# AVR16EB20 device description
Architecture: AVR8X; Family: AVREB
Registers are 8-bit, read-write, reset 0x0 unless marked. A register's access mark holds for its fields unless they carry their own. Offsets are from the block's base; [hi:lo] are bit positions.

## CLKCTRL — Clock controller
Instances: CLKCTRL 0x0060
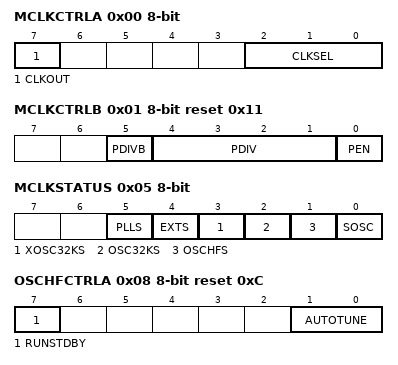
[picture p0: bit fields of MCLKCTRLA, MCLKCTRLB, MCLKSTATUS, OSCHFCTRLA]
0x00 MCLKCTRLA — MCLK Control A
  [7] CLKOUT — System clock out
  [2:0] CLKSEL — Clock select
    0=OSCHF (Internal high-frequency oscillator); 1=OSC32K (Internal 32.768 kHz oscillator); 2=XOSC32K (32.768 kHz crystal oscillator); 3=EXTCLK (External clock); 4=PLL (PLL Oscillator)
0x01 MCLKCTRLB reset 0x11 — MCLK Control B
  [5] PDIVB — Prescaler B division
    0=NONE (No division); 1=DIV4 (Divide by 4)
  [4:1] PDIV — Prescaler division
    0=DIV2 (Divide by 2); 1=DIV4 (Divide by 4); 2=DIV8 (Divide by 8); 3=DIV16 (Divide by 16); 4=DIV32 (Divide by 32); 5=DIV64 (Divide by 64); 8=DIV6 (Divide by 6); 9=DIV10 (Divide by 10); 10=DIV12 (Divide by 12); 11=DIV24 (Divide by 24); 12=DIV48 (Divide by 48)
  [0] PEN — Prescaler enable
0x05 MCLKSTATUS
  [5] PLLS ro — PLL status
  [4] EXTS ro — External Clock status
  [3] XOSC32KS ro — 32.768 kHz Crystal Oscillator status
  [2] OSC32KS ro — 32KHz oscillator status
  [1] OSCHFS ro — High frequency oscillator status
  [0] SOSC ro — System Oscillator changing
0x06 MCLKTIMEBASE
  [4:0] TIMEBASE
0x08 OSCHFCTRLA reset 0xC — OSCHF Control A
  [7] RUNSTDBY — Run in standby
  [1:0] AUTOTUNE — Automatic Oscillator Tune
    0=OFF (Disabled); 1=XOSC32K (Tune against 32.768 kHz Crystal Oscillator)
0x09 OSCHFTUNE
  [7:0] TUNE — Oscillator Tune
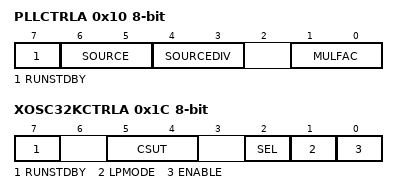
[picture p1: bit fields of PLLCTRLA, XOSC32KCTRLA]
0x10 PLLCTRLA — PLL Control A
  [7] RUNSTDBY — Run in Standby
  [6:5] SOURCE — PLL Source
    0=OSCHF (Internal High Frequency Oscillator); 1=EXTCLK (External Clock)
  [4:3] SOURCEDIV — PLL Source Division
    0=DIV1 (Source undivided); 1=DIV2 (Divide source by 2); 2=DIV4 (Divide source by 4); 3=DIV6 (Divide source by 6)
  [1:0] MULFAC — PLL Multiplication Factor
    0=OFF (PLL Disabled); 2=8X (Multiply by 8); 3=16X (Multiply by 16)
0x11 PLLCTRLB — PLL Control B
  [0] CLKDIV — PLL Output Clock Division
    0=NONE (PLL output clock undivided); 1=DIV2 (PLL output clock divided by 2)
0x18 OSC32KCTRLA — OSC32K Control A
  [7] RUNSTDBY — Run standby
0x1C XOSC32KCTRLA — XOSC32K Control A
  [7] RUNSTDBY — Run standby
  [5:4] CSUT — Crystal startup time
    0=1K (1k cycles); 1=16K (16k cycles); 2=32K (32k cycles); 3=64K (64k cycles)
  [2] SEL — Select
  [1] LPMODE — Low power mode
  [0] ENABLE

## CPU
Instances: CPU 0x0030
0x04 CCP — Configuration Change Protection
  [7:0] CCP — CCP signature
    157=SPM (SPM Instruction Protection); 216=IOREG (IO Register Protection)
0x0D SP 16-bit reset 0x7FFF — Stack Pointer
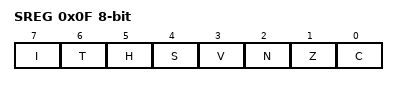
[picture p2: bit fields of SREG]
0x0F SREG — Status Register
  [7] I — Global Interrupt Enable Flag
  [6] T — Transfer Bit
  [5] H — Half Carry Flag
  [4] S — N Exclusive Or V Flag
  [3] V — Two's Complement Overflow Flag
  [2] N — Negative Flag
  [1] Z — Zero Flag
  [0] C — Carry Flag

## CPUINT — Interrupt Controller
Instances: CPUINT 0x0110
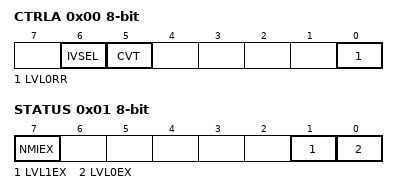
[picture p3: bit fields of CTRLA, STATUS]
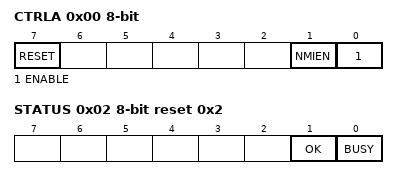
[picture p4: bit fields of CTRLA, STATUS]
0x00 CTRLA — Control A
  [6] IVSEL — Interrupt Vector Select
  [5] CVT — Compact Vector Table
  [0] LVL0RR — Round-robin Scheduling Enable
0x01 STATUS ro
  [7] NMIEX — Non-maskable Interrupt Executing
  [1] LVL1EX — Level 1 Interrupt Executing
  [0] LVL0EX — Level 0 Interrupt Executing
0x02 LVL0PRI — Interrupt Level 0 Priority
  [7:0] LVL0PRI — Interrupt Level Priority
0x03 LVL1VEC — Interrupt Level 1 Priority Vector
  [7:0] LVL1VEC — Interrupt Vector with High Priority

## CRCSCAN
Instances: CRCSCAN 0x0120
0x00 CTRLA — Control A
  [7] RESET — Reset CRC scan
  [1] NMIEN — Enable NMI Trigger
  [0] ENABLE — Enable CRC scan
0x01 CTRLB — Control B
  [1:0] SRC — CRC Source
    0=FLASH (CRC on entire flash); 1=APPLICATION (CRC on boot and appl section of flash); 2=BOOT (CRC on boot section of flash)
0x02 STATUS ro reset 0x2
  [1] OK — CRC Ok
  [0] BUSY — CRC Busy
